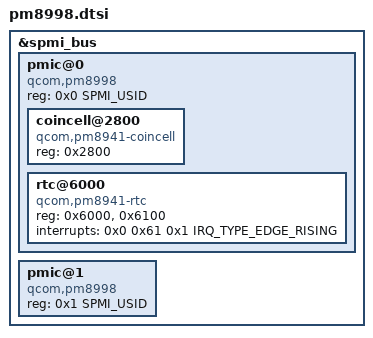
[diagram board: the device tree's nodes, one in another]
// SPDX-License-Identifier: GPL-2.0
#include <dt-bindings/interrupt-controller/irq.h>
#include <dt-bindings/spmi/spmi.h>

&spmi_bus {
	pmic@0 {
		compatible = "qcom,pm8998", "qcom,spmi-pmic";
		reg = <0x0 SPMI_USID>;
		#address-cells = <1>;
		#size-cells = <0>;

		coincell@2800 {
			compatible = "qcom,pm8941-coincell";
			reg = <0x2800>;
		};

		rtc@6000 {
			compatible = "qcom,pm8941-rtc";
			reg = <0x6000>, <0x6100>;
			reg-names = "rtc", "alarm";
			interrupts = <0x0 0x61 0x1 IRQ_TYPE_EDGE_RISING>;
		};
	};

	pmic@1 {
		compatible = "qcom,pm8998", "qcom,spmi-pmic";
		reg = <0x1 SPMI_USID>;
		#address-cells = <1>;
		#size-cells = <0>;
	};
};
